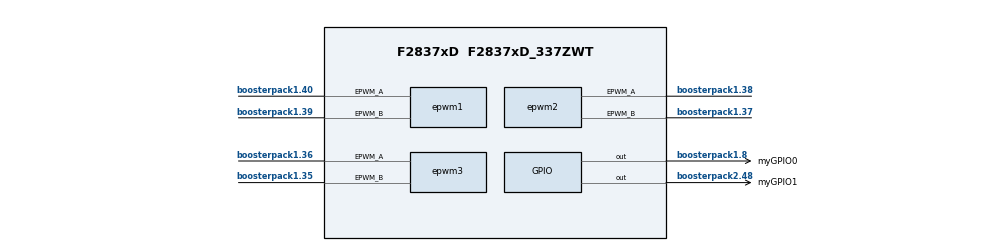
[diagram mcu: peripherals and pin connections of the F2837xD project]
/**
 * @cliArgs --board "/boards/LAUNCHXL_F28379D" --device "F2837xD" --part "F2837xD_337ZWT" --package "F2837xD_337ZWT" --context "CPU1" --product "C2000WARE@5.04.00.00"
 * @versions {"tool":"1.21.0+3721"}
 */

/**
 * Import the modules used in this configuration.
 */
const adc              = scripting.addModule("/driverlib/adc.js", {}, false);
const adc1             = adc.addInstance();
const adc2             = adc.addInstance();
const adc3             = adc.addInstance();
const cmpss            = scripting.addModule("/driverlib/cmpss.js", {}, false);
const cmpss1           = cmpss.addInstance();
const cputimer         = scripting.addModule("/driverlib/cputimer.js", {}, false);
const cputimer1        = cputimer.addInstance();
const dac              = scripting.addModule("/driverlib/dac.js", {}, false);
const dac1             = dac.addInstance();
const dac2             = dac.addInstance();
const epwm             = scripting.addModule("/driverlib/epwm.js", {}, false);
const epwm1            = epwm.addInstance();
const epwm2            = epwm.addInstance();
const epwm3            = epwm.addInstance();
const epwmxbar         = scripting.addModule("/driverlib/epwmxbar.js", {}, false);
const epwmxbar1        = epwmxbar.addInstance();
const gpio             = scripting.addModule("/driverlib/gpio.js", {}, false);
const gpio1            = gpio.addInstance();
const gpio2            = gpio.addInstance();
const inputxbar_input  = scripting.addModule("/driverlib/inputxbar_input.js", {}, false);
const inputxbar_input1 = inputxbar_input.addInstance();
const inputxbar_input2 = inputxbar_input.addInstance();

/**
 * Write custom configuration values to the imported modules.
 */
adc1.adcClockPrescaler              = "ADC_CLK_DIV_4_0";
adc1.soc0SampleWindow               = 16;
adc1.enableInterrupt1               = true;
adc1.enableInterrupt1ContinuousMode = true;
adc1.soc0Channel                    = "ADC_CH_ADCIN2";
adc1.registerInterrupts             = ["1"];
adc1.soc0Trigger                    = "ADC_TRIGGER_CPU1_TINT0";
adc1.soc1Channel                    = "ADC_CH_ADCIN2";
adc1.soc1Trigger                    = "ADC_TRIGGER_CPU1_TINT0";
adc1.soc1SampleWindow               = 16;
adc1.interrupt1SOCSource            = "ADC_SOC_NUMBER1";
adc1.useInterrupts                  = false;
adc1.adcBase                        = "ADCB_BASE";
adc1.soc4Channel                    = "ADC_CH_ADCIN4";
adc1.soc4SampleWindow               = 16;
adc1.soc5Channel                    = "ADC_CH_ADCIN2";
adc1.soc5SampleWindow               = 16;
adc1.soc6Channel                    = "ADC_CH_ADCIN3";
adc1.soc6SampleWindow               = 16;
adc1.$name                          = "ADC_B";
adc1.enableBurstMode                = true;
adc1.burstTrigger                   = "ADC_TRIGGER_CPU1_TINT0";
adc1.burstSize                      = 2;
adc1.enabledSOCs                    = ["ADC_SOC_NUMBER5","ADC_SOC_NUMBER6","ADC_SOC_NUMBER7"];
adc1.soc7Channel                    = "ADC_CH_ADCIN4";
adc1.soc7SampleWindow               = 16;
scripting.suppress("SOC5 is configured for Round Robin\\. With burst mode enabled, the  burst mode trigger will override the selected trigger for this SOC", adc1, "soc5Trigger");
scripting.suppress("SOC6 is configured for Round Robin\\. With burst mode enabled, the  burst mode trigger will override the selected trigger for this SOC", adc1, "soc6Trigger");
scripting.suppress("SOC7 is configured for Round Robin\\. With burst mode enabled, the  burst mode trigger will override the selected trigger for this SOC", adc1, "soc7Trigger");

adc2.adcClockPrescaler = "ADC_CLK_DIV_4_0";
adc2.soc0SampleWindow  = 16;
adc2.soc0Channel       = "ADC_CH_ADCIN2";
adc2.soc1Channel       = "ADC_CH_ADCIN3";
adc2.soc1SampleWindow  = 16;
adc2.soc2Channel       = "ADC_CH_ADCIN4";
adc2.soc2SampleWindow  = 16;
adc2.soc3Channel       = "ADC_CH_ADCIN15";
adc2.soc3SampleWindow  = 16;
adc2.useInterrupts     = false;
adc2.$name             = "ADC_A";
adc2.enableBurstMode   = true;
adc2.burstTrigger      = "ADC_TRIGGER_CPU1_TINT0";
adc2.enabledSOCs       = ["ADC_SOC_NUMBER0","ADC_SOC_NUMBER1","ADC_SOC_NUMBER2","ADC_SOC_NUMBER3","ADC_SOC_NUMBER4"];
adc2.soc4Channel       = "ADC_CH_ADCIN14";
adc2.soc4SampleWindow  = 16;
adc2.burstSize         = 4;
scripting.suppress("SOC0 is configured for Round Robin\\. With burst mode enabled, the  burst mode trigger will override the selected trigger for this SOC", adc2, "soc0Trigger");
scripting.suppress("SOC1 is configured for Round Robin\\. With burst mode enabled, the  burst mode trigger will override the selected trigger for this SOC", adc2, "soc1Trigger");
scripting.suppress("SOC2 is configured for Round Robin\\. With burst mode enabled, the  burst mode trigger will override the selected trigger for this SOC", adc2, "soc2Trigger");
scripting.suppress("SOC3 is configured for Round Robin\\. With burst mode enabled, the  burst mode trigger will override the selected trigger for this SOC", adc2, "soc3Trigger");
scripting.suppress("SOC4 is configured for Round Robin\\. With burst mode enabled, the  burst mode trigger will override the selected trigger for this SOC", adc2, "soc4Trigger");

adc3.adcBase                 = "ADCC_BASE";
adc3.adcClockPrescaler       = "ADC_CLK_DIV_4_0";
adc3.soc7Channel             = "ADC_CH_ADCIN4";
adc3.soc7SampleWindow        = 16;
adc3.soc8Channel             = "ADC_CH_ADCIN2";
adc3.soc8SampleWindow        = 16;
adc3.soc9Channel             = "ADC_CH_ADCIN3";
adc3.soc9SampleWindow        = 16;
adc3.enableBurstMode         = true;
adc3.burstTrigger            = "ADC_TRIGGER_CPU1_TINT0";
adc3.registerInterrupts      = ["1"];
adc3.enabledInts             = ["ADC_INT_NUMBER1"];
adc3.enableInterrupt1        = true;
adc3.$name                   = "ADC_C";
adc3.soc10Channel            = "ADC_CH_ADCIN14";
adc3.soc10SampleWindow       = 16;
adc3.interrupt1SOCSource     = "ADC_SOC_NUMBER10";
adc3.enabledSOCs             = ["ADC_SOC_NUMBER10","ADC_SOC_NUMBER8","ADC_SOC_NUMBER9"];
adc3.burstSize               = 2;
adc3.adcInt1.enableInterrupt = true;
scripting.suppress("SOC8 is configured for Round Robin\\. With burst mode enabled, the  burst mode trigger will override the selected trigger for this SOC", adc3, "soc8Trigger");
scripting.suppress("SOC9 is configured for Round Robin\\. With burst mode enabled, the  burst mode trigger will override the selected trigger for this SOC", adc3, "soc9Trigger");
scripting.suppress("SOC10 is configured for Round Robin\\. With burst mode enabled, the  burst mode trigger will override the selected trigger for this SOC", adc3, "soc10Trigger");

cmpss1.$name        = "myCMPSS0";
cmpss1.enableModule = true;
cmpss1.dacValHigh   = 2048;
cmpss1.cmpssBase    = "CMPSS6_BASE";

cputimer1.$name                    = "myCPUTIMER0";
cputimer1.emulationMode            = "CPUTIMER_EMULATIONMODE_RUNFREE";
cputimer1.timerPeriod              = 4999;
cputimer1.enableInterrupt          = true;
cputimer1.startTimer               = true;
cputimer1.registerInterrupts       = true;
cputimer1.timerInt.enableInterrupt = true;

dac1.$name            = "DAC0";
dac1.enableOutput     = true;
dac1.dacBase          = "DACB_BASE";
dac1.referenceVoltage = "DAC_REF_ADC_VREFHI";

dac2.referenceVoltage = "DAC_REF_ADC_VREFHI";
dac2.enableOutput     = true;
dac2.$name            = "DAC1";

epwm1.epwmTimebase_hsClockDiv                           = "EPWM_HSCLOCK_DIVIDER_1";
epwm1.epwmEventTrigger_EPWM_SOC_A_triggerEnable         = true;
epwm1.epwmEventTrigger_EPWM_SOC_A_triggerSource         = "EPWM_SOC_TBCTR_ZERO_OR_PERIOD";
epwm1.epwmEventTrigger_EPWM_SOC_A_triggerEventPrescalar = "1";
epwm1.$name                                             = "myEPWM1";
epwm1.epwmDeadband_enableFED                            = true;
epwm1.epwmDeadband_delayRED                             = 50;
epwm1.epwmDeadband_delayFED                             = 50;
epwm1.epwmDeadband_polarityFED                          = "EPWM_DB_POLARITY_ACTIVE_LOW";
epwm1.epwmDeadband_enableRED                            = true;
epwm1.epwm.$assign                                      = "EPWM1";
epwm1.epwm.epwm_aPin.$assign                            = "boosterpack1.40";
epwm1.epwm.epwm_bPin.$assign                            = "boosterpack1.39";

epwm2.$name                                             = "myEPWM2";
epwm2.epwmTimebase_hsClockDiv                           = "EPWM_HSCLOCK_DIVIDER_1";
epwm2.epwmDeadband_polarityFED                          = "EPWM_DB_POLARITY_ACTIVE_LOW";
epwm2.epwmDeadband_enableRED                            = true;
epwm2.epwmDeadband_enableFED                            = true;
epwm2.epwmDeadband_redShadowMode                        = true;
epwm2.epwmDeadband_delayRED                             = 50;
epwm2.epwmDeadband_fedShadowMode                        = true;
epwm2.epwmDeadband_delayFED                             = 50;
epwm2.epwmEventTrigger_EPWM_SOC_A_triggerEnable         = true;
epwm2.epwmEventTrigger_EPWM_SOC_A_triggerSource         = "EPWM_SOC_TBCTR_ZERO_OR_PERIOD";
epwm2.epwmEventTrigger_EPWM_SOC_A_triggerEventPrescalar = "1";
epwm2.epwm.$assign                                      = "EPWM2";
epwm2.epwm.epwm_aPin.$assign                            = "boosterpack1.38";
epwm2.epwm.epwm_bPin.$assign                            = "boosterpack1.37";

epwm3.$name                                             = "myEPWM3";
epwm3.epwmTimebase_hsClockDiv                           = "EPWM_HSCLOCK_DIVIDER_1";
epwm3.epwmDeadband_polarityFED                          = "EPWM_DB_POLARITY_ACTIVE_LOW";
epwm3.epwmDeadband_enableRED                            = true;
epwm3.epwmDeadband_enableFED                            = true;
epwm3.epwmDeadband_redShadowMode                        = true;
epwm3.epwmDeadband_delayRED                             = 50;
epwm3.epwmDeadband_fedShadowMode                        = true;
epwm3.epwmDeadband_delayFED                             = 50;
epwm3.epwmEventTrigger_EPWM_SOC_A_triggerEnable         = true;
epwm3.epwmEventTrigger_EPWM_SOC_A_triggerSource         = "EPWM_SOC_TBCTR_ZERO_OR_PERIOD";
epwm3.epwmEventTrigger_EPWM_SOC_A_triggerEventPrescalar = "1";
epwm3.epwm.$assign                                      = "EPWM3";
epwm3.epwm.epwm_aPin.$assign                            = "boosterpack1.36";
epwm3.epwm.epwm_bPin.$assign                            = "boosterpack1.35";

epwmxbar1.$name     = "myEPWMXBAR0";
epwmxbar1.muxesUsed = ["XBAR_MUX10"];

gpio1.$name                     = "myGPIO0";
gpio1.useInterrupt              = true;
gpio1.gpioPin.$assign           = "boosterpack1.8";
gpio1.xint.intType              = "GPIO_INT_TYPE_BOTH_EDGES";
gpio1.xint.registerInterrupts   = true;
gpio1.xint.enableInt            = true;
gpio1.xint.xInt.enableInterrupt = true;

gpio2.$name           = "myGPIO1";
gpio2.gpioPin.$assign = "boosterpack2.48";

inputxbar_input1.$name         = "myINPUTXBARINPUT0";
gpio1.xint.inputxbar           = inputxbar_input1;
inputxbar_input1.inputxbarGpio = "GPIO22";

inputxbar_input2.$name         = "myINPUTXBARINPUT1";
inputxbar_input2.inputxbarGpio = "GPIO52";
